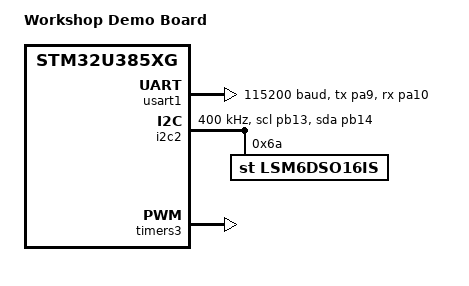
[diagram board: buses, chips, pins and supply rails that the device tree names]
/dts-v1/;
#include <st/u3/stm32u385Xg.dtsi>
#include <st/u3/stm32u385rgtxq-pinctrl.dtsi>
#include <zephyr/dt-bindings/sensor/lsm6dso16is.h>

/ {
	model = "Workshop Demo Board";
	compatible = "demo";

	chosen {
		zephyr,console = &usart1;
		zephyr,shell-uart = &usart1;
		zephyr,sram = &sram0;
		zephyr,flash = &flash0;
	};

	aliases {
		accelerometer = &lsm6dso16is;
		buzzer = &pwm1;
	};
};

// MSIS requires LSE clock to be enabled for auto-calibration
&clk_lse {
	status = "okay";
};

&clk_msis {
	status = "okay";
	msi-pll-mode;
	msi-range = <0>; /* 96MHz (reset value) */
};

&rcc {
	clocks = <&clk_msis>;
	clock-frequency = <DT_FREQ_M(96)>;
	ahb-prescaler = <1>;
	apb1-prescaler = <1>;
	apb2-prescaler = <1>;
	apb3-prescaler = <1>;
};

&usart1 {
	pinctrl-0 = <&usart1_tx_pa9 &usart1_rx_pa10>;
	pinctrl-names = "default";
	current-speed = <115200>;
	status = "okay";
};

&i2c2 {
	pinctrl-0 = <&i2c2_scl_pb13 &i2c2_sda_pb14>; // Arduino D15 + D14
	pinctrl-names = "default";
	clock-frequency = <I2C_BITRATE_FAST>;
	status = "okay";

	lsm6dso16is: lsm6dso16is@6a {
		compatible = "st,lsm6dso16is";
		reg = <0x6a>;
		accel-range = <LSM6DSO16IS_DT_FS_4G>;
		accel-odr = <LSM6DSO16IS_DT_ODR_104Hz_HP>;
		gyro-range = <LSM6DSO16IS_DT_FS_500DPS>;
		gyro-odr = <LSM6DSO16IS_DT_ODR_104Hz_HP>;
		status = "okay";
	};
};

&timers3 {
	st,prescaler = <95>;
	status = "okay";

	pwm1: pwm {
		pinctrl-0 = <&tim3_ch2_pc7>; // Arduino D8
		pinctrl-names = "default";
		status = "okay";
	};
};
